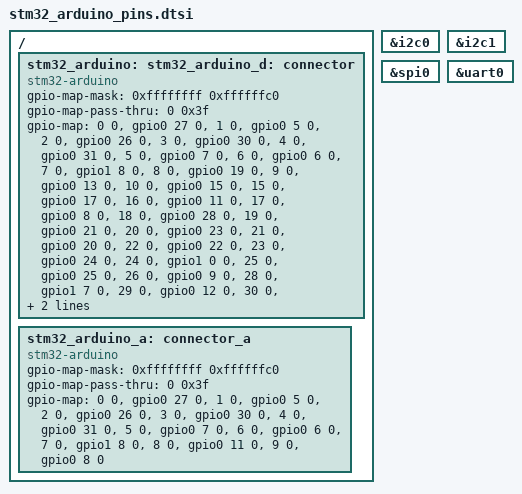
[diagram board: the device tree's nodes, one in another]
/*
 * Copyright (c) 2020 Derek Schmell
 *
 * SPDX-License-Identifier: MIT
 */

/ {
	stm32_arduino: connector {
		compatible = "stm32-arduino";
		#gpio-cells = <2>;
		gpio-map-mask = <0xffffffff 0xffffffc0>;
		gpio-map-pass-thru = <0 0x3f>;
		gpio-map
			= <0 0 &gpio0 27  0>	/* D0/A0 	A0  */ 			
			, <1 0 &gpio0 5   0>	/* D1/A1 	A1  */			
			, <2 0 &gpio0 26  0>	/* D2/A2  	A2  */			
			, <3 0 &gpio0 30  0>	/* D3/A3    A3  */			
			, <4 0 &gpio0 31  0>	/* D4/A4 	A4  */		
			, <5 0 &gpio0 7   0>	/* D5/A5  	A5  */
			, <6 0 &gpio0 6   0>	/* D6/A6 	A6  */
			, <7 0 &gpio1 8   0>	/* D7/A7    A7  */
			, <8 0 &gpio0 19  0>	/* D8   	A8  */
			, <9 0 &gpio0 13  0>	/* D9   	A9  */
			, <10 0 &gpio0 15 0>	/* D10  	A10 */
			, <15 0 &gpio0 17 0>	/* D15  	A15 */
			, <16 0 &gpio0 11 0>    /* D16/A8  	B0  */
			, <17 0 &gpio0 8  0>	/* D17/A9  	B1  */
			, <18 0 &gpio0 28 0> 	/* D18  	B2  */
			, <19 0 &gpio0 21 0>	/* D19  	B3  */
			, <20 0 &gpio0 23 0>	/* D20  	B4  */
			, <21 0 &gpio0 20 0>	/* D21  	B5  */
			, <22 0 &gpio0 22 0>	/* D22	    B6  */ 			
			, <23 0 &gpio0 24 0>	/* D23 	    B7  */			
			, <24 0 &gpio1 0  0> 	/* D24	    B8  */			
			, <25 0 &gpio0 25 0>	/* D25   	B9  */			
			, <26 0 &gpio0 9  0>	/* D26  	B10 */		
			, <28 0 &gpio1 7  0>	/* D28 	    B12 */
			, <29 0 &gpio0 12 0>	/* D29  	B13 */
			, <30 0 &gpio0 16 0>	/* D30    	B14 */
			, <31 0 &gpio0 14 0>	/* D31  	B15 */
			, <45 0 &gpio1 5  0>	/* D45  	C13 */
			, <46 0 &gpio0 1  0>	/* D46  	C14 */
			, <47 0 &gpio0 0  0>	/* D47  	C15 */
			;
	};

	stm32_arduino_a: connector_a {
		compatible = "stm32-arduino";
		#gpio-cells = <2>;
		gpio-map-mask = <0xffffffff 0xffffffc0>;
		gpio-map-pass-thru = <0 0x3f>;
		gpio-map
			= <0 0 &gpio0 27  0>	/* D0/A0 	A0  */ 			
			, <1 0 &gpio0 5   0>	/* D1/A1 	A1  */			
			, <2 0 &gpio0 26  0>	/* D2/A2  	A2  */			
			, <3 0 &gpio0 30  0>	/* D3/A3    A3  */			
			, <4 0 &gpio0 31  0>	/* D4/A4 	A4  */		
			, <5 0 &gpio0 7   0>	/* D5/A5  	A5  */
			, <6 0 &gpio0 6   0>	/* D6/A6 	A6  */
			, <7 0 &gpio1 8   0>	/* D7/A7    A7  */
			, <8 0 &gpio0 11  0>    /* D16/A8  	B0  */
			, <9 0 &gpio0 8   0>	/* D17/A9  	B1  */
			;
	};
};

stm32_arduino_d: &stm32_arduino {};
stm32_arduino_i2c0: &i2c0 {};
stm32_arduino_i2c1: &i2c1 {};
stm32_arduino_spi0: &spi0 {};
stm32_arduino_spi1: &spi0 {};
stm32_arduino_serial: &uart0 {};
